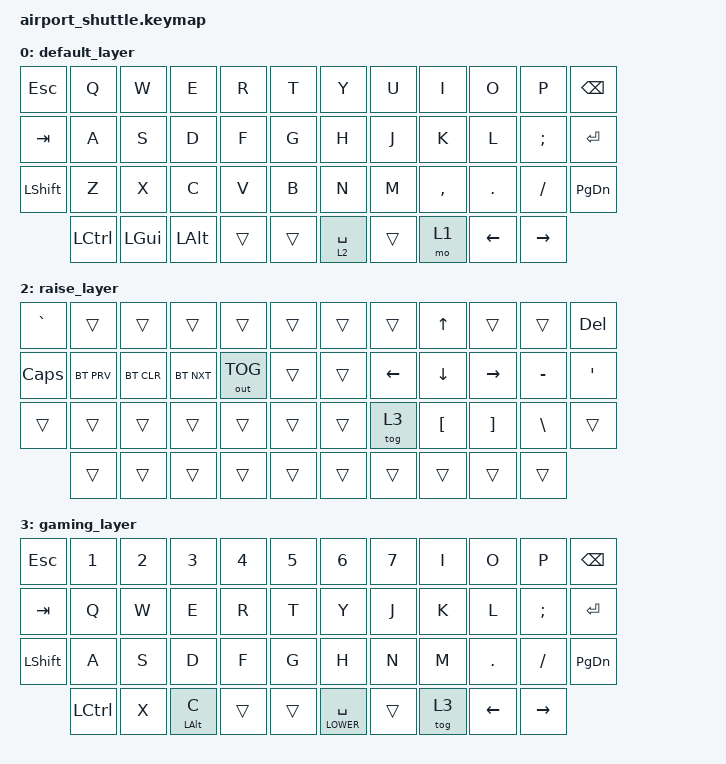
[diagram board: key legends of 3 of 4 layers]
#include <behaviors.dtsi>
#include <dt-bindings/zmk/keys.h>
#include <dt-bindings/zmk/bt.h>
#include <dt-bindings/zmk/outputs.h>

#define DEFAULT 0
#define LOWER   1
#define RAISE   2
#define GAMING  3

/ {
  keymap {
    compatible = "zmk,keymap";

    default_layer {
// -----------------------------------------------------------------------------------------
// |  ESC  |  Q   |  W   |  E   |  R   |  T   |   Y   |  U    |  I   |  O   |   P   | BSPC   |
// |  TAB  |  A   |  S   |  D   |  F   |  G   |   H   |  J    |  K   |  L   |   ;   |  RET   |
// | SHIFT |  Z   |  X   |  C   |  V   |  B   |   N   |  M    |  ,   |  .   |   UP  |  ---   |
// | LCTRL | LGUI | LALT | ---  | ---- |     SPACE    |  ---- | ---- | FN | LFT  |  RT |
      bindings = <
  &kp ESC       &kp Q    &kp W &kp E &kp R &kp T  &kp Y   &kp U  &kp I    &kp O   &kp P    &kp BKSP 
  &kp TAB       &kp A  &kp S &kp D &kp F &kp G  &kp H   &kp J  &kp K    &kp L   &kp SCLN &kp RET
  &kp LSHFT     &kp Z    &kp X &kp C &kp V &kp B  &kp N   &kp M  &kp CMMA &kp DOT &kp SLASH &kp PG_DN
  &kp LCTRL     &kp LEFT_GUI &kp LALT &trans &trans &lt 2 SPACE &trans &mo 1 &kp LEFT &kp RIGHT
      >;
      sensor-bindings = <&inc_dec_kp C_VOL_UP C_VOL_DN>;
    };


      lower_layer {
      bindings = <
      &trans &kp F1 &kp F2 &kp F3 &kp F4 &kp F5 &kp F6 &kp F7 &kp F8 &kp F9 &kp F10 &kp F11 
      &trans &kp NUM_1 &kp NUM_2 &kp NUM_3 &kp NUM_4 &kp NUM_5 &kp NUM_6 &kp NUM_7 &kp NUM_8 &kp NUM_9 &kp NUM_0 &kp EQUAL
      &trans &trans &trans &trans &trans &trans &trans &trans &trans &trans &trans &trans
      &trans &trans &trans &trans &trans &trans &trans &trans &trans &trans &trans
      >;
    };
    
      raise_layer {
      bindings = <
      &kp GRAVE &trans &trans &trans &trans &trans &trans &trans &kp UP &trans &trans &kp DEL
      &kp CAPS &bt BT_PRV &bt BT_CLR &bt BT_NXT &out OUT_TOG &trans &trans &kp LEFT &kp DOWN &kp RIGHT &kp MINUS &kp APOS
      &trans &trans &trans &trans &trans &trans &trans &tog 3 &kp LBKT &kp RBKT &kp BSLH &trans
      &trans &trans &trans &trans &trans &trans &trans &trans &trans &trans
      >;
    };
    
    gaming_layer {
      bindings = <
  &kp ESC       &kp NUM_1 &kp NUM_2 &kp NUM_3 &kp NUM_4 &kp NUM_5 &kp NUM_6 &kp NUM_7  &kp I    &kp O   &kp P    &kp BKSP 
  &kp TAB       &kp Q  &kp W &kp E &kp R &kp T  &kp Y   &kp J  &kp K    &kp L   &kp SCLN &kp RET
  &kp LSHFT     &kp A    &kp S &kp D &kp F &kp G  &kp H   &kp N  &kp M &kp DOT &kp SLASH &kp PG_DN
  &kp LCTRL     &kp X &mt LALT C &trans &trans &lt LOWER SPACE &trans &tog 3 &kp LEFT &kp RIGHT
      >;
    };
  };
};
